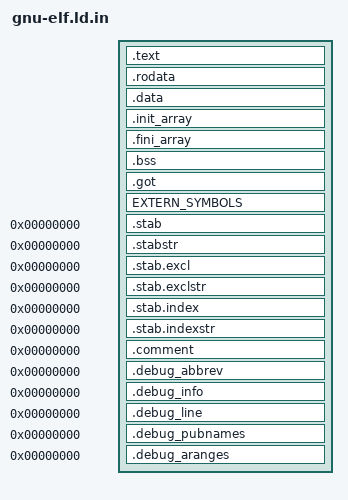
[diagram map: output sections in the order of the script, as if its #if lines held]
/****************************************************************************
 * libs/libc/elf/gnu-elf.ld.in
 *
 * Licensed to the Apache Software Foundation (ASF) under one or more
 * contributor license agreements.  See the NOTICE file distributed with
 * this work for additional information regarding copyright ownership.  The
 * ASF licenses this file to you under the Apache License, Version 2.0 (the
 * "License"); you may not use this file except in compliance with the
 * License.  You may obtain a copy of the License at
 *
 *   http://www.apache.org/licenses/LICENSE-2.0
 *
 * Unless required by applicable law or agreed to in writing, software
 * distributed under the License is distributed on an "AS IS" BASIS, WITHOUT
 * WARRANTIES OR CONDITIONS OF ANY KIND, either express or implied.  See the
 * License for the specific language governing permissions and limitations
 * under the License.
 *
 ****************************************************************************/


#include <nuttx/config.h>

#if defined(CONFIG_BUILD_KERNEL) && defined(CONFIG_BINFMT_ELF_EXECUTABLE)
#  define __ASSEMBLY__
#  include <nuttx/addrenv.h>

#  define TEXT CONFIG_ARCH_TEXT_VBASE
#  define DATA CONFIG_ARCH_DATA_VBASE + ARCH_DATA_RESERVE_SIZE

#else
#  ifndef TEXT
#    define TEXT 0x0
#  endif
#  ifndef DATA
#    define DATA
#  endif
#endif

#ifndef EXTERN_SYMBOLS
#  define EXTERN_SYMBOLS
#endif

#define SECTIONS_ALIGN CONFIG_LIBC_ELF_SECTION_ALIGNMENT

SECTIONS
{
  .text TEXT : SUBALIGN(SECTIONS_ALIGN)
    {
      _stext = . ;
      *(.text)
      *(.text.*)
      *(.gnu.warning)
      *(.stub)
      *(.glue_7)
      *(.glue_7t)
      *(.jcr)
      . = ALIGN(SECTIONS_ALIGN);
      _etext = . ;
    }

  .rodata :
    {
      _srodata = . ;
      *(.rodata)
      *(.rodata1)
      *(.rodata.*)
      *(.gnu.linkonce.r*)
      . = ALIGN(SECTIONS_ALIGN);
      _erodata = . ;
    }

  _eronly = ABSOLUTE(.);
  .data DATA : AT(_eronly) SUBALIGN(SECTIONS_ALIGN)
    {
      _sdata = . ;
      *(.data)
      *(.data1)
      *(.data.*)
      *(.gnu.linkonce.d*)
      . = ALIGN(SECTIONS_ALIGN);
      _edata = . ;
    }

  .init_array :
    {
      _sinit = .;
      _sctors = .;
      KEEP(*(SORT_BY_INIT_PRIORITY(.init_array.*) SORT_BY_INIT_PRIORITY(.ctors.*)))
      KEEP(*(.init_array .ctors))
      . = ALIGN(SECTIONS_ALIGN);
      _einit = .;
      _ectors = .;
    }

  .fini_array :
    {
      _sfini = .;
      _sdtors = .;
      KEEP (*(.dtors))
      KEEP (*(.fini_array))
      KEEP (*(SORT(.fini_array.*)))
      . = ALIGN(SECTIONS_ALIGN);
      _efini = .;
      _edtors = .;
    }

  .bss :
    {
      _sbss = . ;
      *(.bss)
      *(.bss.*)
      *(.sbss)
      *(.sbss.*)
      *(.gnu.linkonce.b*)
      *(COMMON)
      . = ALIGN(SECTIONS_ALIGN);
      _ebss = . ;

#ifdef HEAPSIZE
      _sheap = .;
      . = . + HEAPSIZE;
      _eheap = .;
#endif
    }

  .got :
    {
      *(.got*)
    }

  EXTERN_SYMBOLS

    /* Stabs debugging sections.    */

    .stab 0 : { *(.stab) }
    .stabstr 0 : { *(.stabstr) }
    .stab.excl 0 : { *(.stab.excl) }
    .stab.exclstr 0 : { *(.stab.exclstr) }
    .stab.index 0 : { *(.stab.index) }
    .stab.indexstr 0 : { *(.stab.indexstr) }
    .comment 0 : { *(.comment) }
    .debug_abbrev 0 : { *(.debug_abbrev) }
    .debug_info 0 : { *(.debug_info) }
    .debug_line 0 : { *(.debug_line) }
    .debug_pubnames 0 : { *(.debug_pubnames) }
    .debug_aranges 0 : { *(.debug_aranges) }
}
